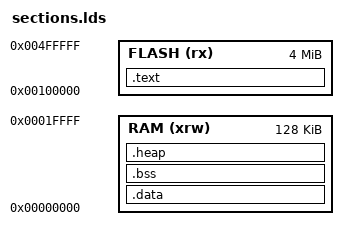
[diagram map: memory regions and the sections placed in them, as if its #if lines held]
/*
 *
 *  Copyright (C) 2017  Clifford Wolf <clifford@clifford.at>
 *                      Cristian Balint <cristian dot balint at gmail dot com>
 *
 *  Permission to use, copy, modify, and/or distribute this software for any
 *  purpose with or without fee is hereby granted, provided that the above
 *  copyright notice and this permission notice appear in all copies.
 *
 *  THE SOFTWARE IS PROVIDED "AS IS" AND THE AUTHOR DISCLAIMS ALL WARRANTIES
 *  WITH REGARD TO THIS SOFTWARE INCLUDING ALL IMPLIED WARRANTIES OF
 *  MERCHANTABILITY AND FITNESS. IN NO EVENT SHALL THE AUTHOR BE LIABLE FOR
 *  ANY SPECIAL, DIRECT, INDIRECT, OR CONSEQUENTIAL DAMAGES OR ANY DAMAGES
 *  WHATSOEVER RESULTING FROM LOSS OF USE, DATA OR PROFITS, WHETHER IN AN
 *  ACTION OF CONTRACT, NEGLIGENCE OR OTHER TORTIOUS ACTION, ARISING OUT OF
 *  OR IN CONNECTION WITH THE USE OR PERFORMANCE OF THIS SOFTWARE.
 *
 */

#ifdef ICEBREAKER
#  define MEM_TOTAL 0x20000 /* 128 KB */
#else
#  error "Set -DICEBREAKER or -DHX8KDEMO when compiling firmware.c"
#endif

MEMORY
{
    FLASH (rx)      : ORIGIN = 0x00100000, LENGTH = 0x400000 /* entire flash, 4 MiB */
    RAM (xrw)       : ORIGIN = 0x00000000, LENGTH = MEM_TOTAL
}

SECTIONS {
    /* The program code and other data goes into FLASH */
    .text :
    {
        . = ALIGN(4);
        *(.text)           /* .text sections (code) */
        *(.text*)          /* .text* sections (code) */
        *(.rodata)         /* .rodata sections (constants, strings, etc.) */
        *(.rodata*)        /* .rodata* sections (constants, strings, etc.) */
        *(.srodata)        /* .rodata sections (constants, strings, etc.) */
        *(.srodata*)       /* .rodata* sections (constants, strings, etc.) */
        . = ALIGN(4);
        _etext = .;        /* define a global symbol at end of code */
        _sidata = _etext;  /* This is used by the startup in order to initialize the .data secion */
    } >FLASH


    /* This is the initialized data section
    The program executes knowing that the data is in the RAM
    but the loader puts the initial values in the FLASH (inidata).
    It is one task of the startup to copy the initial values from FLASH to RAM. */
    .data : AT ( _sidata )
    {
        . = ALIGN(4);
        _sdata = .;        /* create a global symbol at data start; used by startup code in order to initialise the .data section in RAM */
        _ram_start = .;    /* create a global symbol at ram start for garbage collector */
        . = ALIGN(4);
        *(.data)           /* .data sections */
        *(.data*)          /* .data* sections */
        *(.sdata)           /* .sdata sections */
        *(.sdata*)          /* .sdata* sections */
        . = ALIGN(4);
        _edata = .;        /* define a global symbol at data end; used by startup code in order to initialise the .data section in RAM */
    } >RAM

    /* Uninitialized data section */
    .bss :
    {
        . = ALIGN(4);
        _sbss = .;         /* define a global symbol at bss start; used by startup code */
        *(.bss)
        *(.bss*)
        *(.sbss)
        *(.sbss*)
        *(COMMON)

        . = ALIGN(4);
        _ebss = .;         /* define a global symbol at bss end; used by startup code */
    } >RAM

    /* this is to define the start of the heap, and make sure we have a minimum size */
    .heap :
    {
        . = ALIGN(4);
        _heap_start = .;    /* define a global symbol at heap start */
    } >RAM
}
